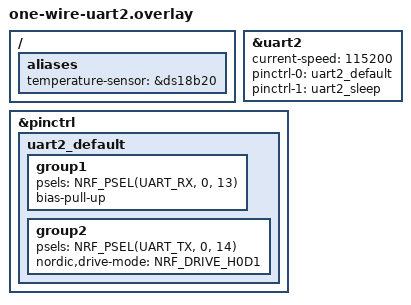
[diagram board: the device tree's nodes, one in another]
/*
 * Copyright (c) 2023 Achim Kraus CloudCoap.net
 *
 * See the NOTICE file(s) distributed with this work for additional
 * information regarding copyright ownership.
 *
 * This program and the accompanying materials are made available under the
 * terms of the Eclipse Public License 2.0 which is available at
 * http://www.eclipse.org/legal/epl-2.0
 *
 * Based on 
 * https://github.com/zephyrproject-rtos/zephyr/blob/main/samples/sensor/ds18b20/boards/nrf52840dk_nrf52840.overlay
 *
 * SPDX-License-Identifier: EPL-2.0 or Apache-2.0
 */

/*
 * Usage: 
 *
 * west build -d build_feather_nrf9160_ns -b circuitdojo_feather_nrf9160_ns --pristine -- \
 *    -DOVERLAY_CONFIG="one-wire-prj.conf" -DDTC_OVERLAY_FILE="boards/circuitdojo_feather_nrf9160_ns.overlay;one-wire-uart2.overlay"
 */

one_wire_serial: &uart2 {
	status = "okay";
	current-speed = <115200>;
	pinctrl-0 = <&uart2_default>;
	pinctrl-1 = <&uart2_sleep>;
	pinctrl-names = "default", "sleep";
};

#include "serial_overlay.dtsi"

&pinctrl {
	uart2_default: uart2_default {
		group1 {
			psels = <NRF_PSEL(UART_RX, 0, 13)>;
			bias-pull-up;
		};
		group2 {
			psels = <NRF_PSEL(UART_TX, 0, 14)>;
			/* max. 5mA drive strength: */
			nordic,drive-mode = <NRF_DRIVE_H0D1>;
		};
	};
};

/ {
	/*
	 * Map the devices to the aliases of the application.
	 */
	aliases {
		/* alias for sensor with SENSOR_CHAN_AMBIENT_TEMP channel */
		temperature-sensor = &ds18b20;
	};
};
